# Timer_A2_1 register map
Vendor: Texas Instruments
Peripheral module from a debugger description file (folder msp430).
Registers are 16-bit, access not given, no defined reset value unless marked. A register's access mark holds for its fields unless they carry their own. Offsets are as the file gives them; lines under a group give offsets from that group; [hi:lo] are bit positions; {n}, {i} and the like mark numbered series; 'fields as' and 'values as' point back to an identical list; <NAME> marks a mode.

## Timer_A2
0x12E TAIV — Timer A Interrupt Vector Word
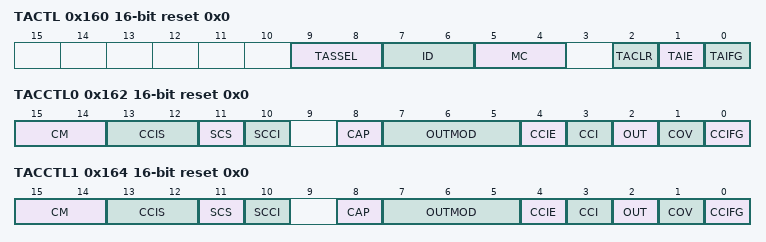
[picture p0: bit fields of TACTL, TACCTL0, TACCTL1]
0x160 TACTL rw reset 0x0 — Timer A Control
  [9:8] TASSEL — Timer A clock source select 1
    0=Timer A clock source select: 0 - TACLK; 1=Timer A clock source select: 1 - ACLK; 2=Timer A clock source select: 2 - SMCLK; 3=Timer A clock source select: 3 - INCLK
  [7:6] ID — Timer A clock input divider 1
    0=Timer A input divider: 0 - /1; 1=Timer A input divider: 1 - /2; 2=Timer A input divider: 2 - /4; 3=Timer A input divider: 3 - /8
  [5:4] MC — Timer A mode control 1
    0=Timer A mode control: 0 - Stop; 1=Timer A mode control: 1 - Up to CCR0; 2=Timer A mode control: 2 - Continous up; 3=Timer A mode control: 3 - Up/Down
  [2] TACLR — Timer A counter clear
  [1] TAIE — Timer A counter interrupt enable
  [0] TAIFG — Timer A counter interrupt flag
0x162 TACCTL0 rw reset 0x0 — Timer A Capture/Compare Control 0
  [15:14] CM — Capture mode 1
    0=Capture mode: 0 - disabled; 1=Capture mode: 1 - pos. edge; 2=Capture mode: 1 - neg. edge; 3=Capture mode: 1 - both edges
  [13:12] CCIS — Capture input select 1
    0=Capture input select: 0 - CCIxA; 1=Capture input select: 1 - CCIxB; 2=Capture input select: 2 - GND; 3=Capture input select: 3 - Vcc
  [11] SCS — Capture sychronize
  [10] SCCI — Latched capture signal (read)
  [8] CAP — Capture mode: 1 /Compare mode : 0
  [7:5] OUTMOD — Output mode 2
    0=PWM output mode: 0 - output only; 1=PWM output mode: 1 - set; 2=PWM output mode: 2 - PWM toggle/reset; 3=PWM output mode: 3 - PWM set/reset; 4=PWM output mode: 4 - toggle; 5=PWM output mode: 5 - Reset; 6=PWM output mode: 6 - PWM toggle/set; 7=PWM output mode: 7 - PWM reset/set
  [4] CCIE — Capture/compare interrupt enable
  [3] CCI — Capture input signal (read)
  [2] OUT — PWM Output signal if output mode 0
  [1] COV — Capture/compare overflow flag
  [0] CCIFG — Capture/compare interrupt flag
0x164 TACCTL1 rw reset 0x0 — Timer A Capture/Compare Control 1
  fields as TACCTL0
0x170 TAR — Timer A Counter Register
0x172 TACCR0 — Timer A Capture/Compare 0
0x174 TACCR1 — Timer A Capture/Compare 1
